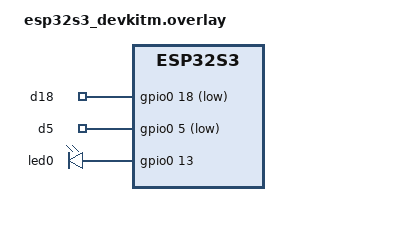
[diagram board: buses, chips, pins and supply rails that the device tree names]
/ {
    aliases {
        push-button1= &button_1;
        push-button2 = &button_2;
        yellow-led = &led0;
    };

    custom-buttons {
        button_1: custom_button_1 {
            compatible = "custom,button";
            pin = <&d18>;
        };

        button_2: custom_button_2 {
            compatible = "custom,button";
            pin = <&d5>;
        };
    };

    gpio-keys {
        compatible = "gpio-keys";
        debounce-interval-ms = <50>;
        polling-mode;

        d18: gpio18 {
            gpios = <&gpio0 18 (GPIO_ACTIVE_LOW | GPIO_PULL_UP)>;
        };

        d5: gpio5 {
            gpios = <&gpio0 5 (GPIO_ACTIVE_LOW | GPIO_PULL_UP)>;
        };
    };

    leds {
        compatible = "gpio-leds";

        led0: yellow_led {
            gpios = <&gpio0 13 GPIO_ACTIVE_HIGH>;
        };
    };
};
